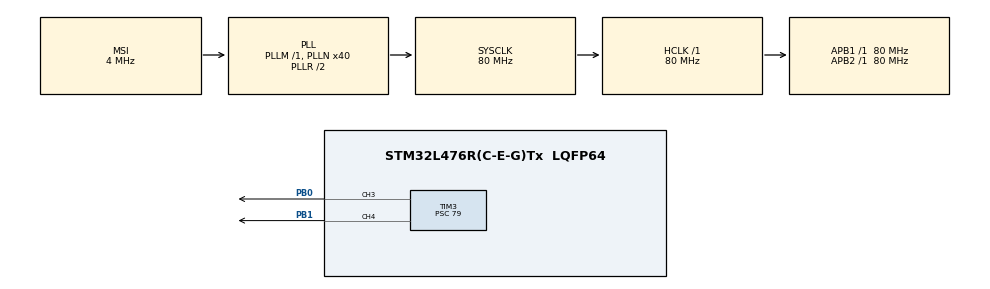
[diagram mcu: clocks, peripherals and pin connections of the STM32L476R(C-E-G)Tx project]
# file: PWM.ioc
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Mcu.Family=STM32L4
Mcu.Name=STM32L476R(C-E-G)Tx
Mcu.Package=LQFP64
NVIC.PriorityGroup=NVIC_PRIORITYGROUP_4
PA13\ (JTMS-SWDIO).Mode=Serial_Wire
PA13\ (JTMS-SWDIO).Signal=SYS_JTMS-SWDIO
PA14\ (JTCK-SWCLK).Mode=Serial_Wire
PA14\ (JTCK-SWCLK).Signal=SYS_JTCK-SWCLK
PB0.Signal=S_TIM3_CH3
PB1.Signal=S_TIM3_CH4
ProjectManager.HeapSize=0x200
ProjectManager.StackSize=0x400
ProjectManager.TargetToolchain=MDK-ARM V5.32
RCC.ADCFreq_Value=16000000
RCC.AHBFreq_Value=80000000
RCC.APB1Freq_Value=80000000
RCC.APB1TimFreq_Value=80000000
RCC.APB2Freq_Value=80000000
RCC.APB2TimFreq_Value=80000000
RCC.CortexFreq_Value=80000000
RCC.HCLKFreq_Value=80000000
RCC.HSE_VALUE=8000000
RCC.HSI_VALUE=16000000
RCC.LSE_VALUE=32768
RCC.MSI_VALUE=4000000
RCC.PLLN=40
RCC.SYSCLKFreq_VALUE=80000000
RCC.SYSCLKSource=RCC_SYSCLKSOURCE_PLLCLK
RCC.USBFreq_Value=16000000
RCC.VCOOutputFreq_Value=160000000
SH.S_TIM3_CH3.0=TIM3_CH3,PWM Generation3 CH3
SH.S_TIM3_CH4.0=TIM3_CH4,PWM Generation4 CH4
TIM3.Channel-PWM\ Generation3\ CH3=TIM_CHANNEL_3
TIM3.Channel-PWM\ Generation4\ CH4=TIM_CHANNEL_4
TIM3.Period=2000
TIM3.Prescaler=79
VP_TIM3_VS_ClockSourceINT.Mode=Internal
board=custom

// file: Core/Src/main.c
/* USER CODE BEGIN Header */
/**
  ******************************************************************************
  * @file           : main.c
  * @brief          : Main program body
  ******************************************************************************
  * @attention
  *
  * Copyright (c) 2026 STMicroelectronics.
  * All rights reserved.
  *
  * This software is licensed under terms that can be found in the LICENSE file
  * in the root directory of this software component.
  * If no LICENSE file comes with this software, it is provided AS-IS.
  *
  ******************************************************************************
  */
/* USER CODE END Header */
#include "main.h"

TIM_HandleTypeDef htim3;

/* USER CODE BEGIN PV */
void pwm_set_duty(TIM_HandleTypeDef *htim, uint32_t Channel, uint8_t duty)
{

	uint32_t ccr;
	if(duty>100)
	{
		duty=100;
	}
	ccr=((htim->Instance->ARR+1)*duty)/100;
	__HAL_TIM_SET_COMPARE(htim, Channel, ccr);
}
/* USER CODE END PV */

void SystemClock_Config(void);
static void MX_GPIO_Init(void);
static void MX_TIM3_Init(void);

int main(void)
{

  /* MCU Configuration--------------------------------------------------------*/

  /* Reset of all peripherals, Initializes the Flash interface and the Systick. */
  HAL_Init();

  /* Configure the system clock */
  SystemClock_Config();

  /* Initialize all configured peripherals */
  MX_GPIO_Init();
  MX_TIM3_Init();
  /* USER CODE BEGIN 2 */
	HAL_TIM_PWM_Start(&htim3, TIM_CHANNEL_3);
	HAL_TIM_PWM_Start(&htim3, TIM_CHANNEL_4);
	//thay doi duty cycle
	//htim3.Instance->CCR3 =1999;

  /* USER CODE END 2 */

  /* Infinite loop */
  while (1)
  {

    /* USER CODE BEGIN 3 */

		for(uint16_t i=0;i<=100;i++)
		{
			//pwm_set_duty(&htim3, TIM_CHANNEL_3, i);
			pwm_set_duty(&htim3, TIM_CHANNEL_4, i);
			HAL_Delay(5);
		}
  }
  /* USER CODE END 3 */
}

void SystemClock_Config(void)
{
  RCC_OscInitTypeDef RCC_OscInitStruct = {0};
  RCC_ClkInitTypeDef RCC_ClkInitStruct = {0};

  /** Configure the main internal regulator output voltage
  */
  if (HAL_PWREx_ControlVoltageScaling(PWR_REGULATOR_VOLTAGE_SCALE1) != HAL_OK)
  {
    Error_Handler();
  }

  /** Initializes the RCC Oscillators according to the specified parameters
  * in the RCC_OscInitTypeDef structure.
  */
  RCC_OscInitStruct.OscillatorType = RCC_OSCILLATORTYPE_MSI;
  RCC_OscInitStruct.MSIState = RCC_MSI_ON;
  RCC_OscInitStruct.MSICalibrationValue = 0;
  RCC_OscInitStruct.MSIClockRange = RCC_MSIRANGE_6;
  RCC_OscInitStruct.PLL.PLLState = RCC_PLL_ON;
  RCC_OscInitStruct.PLL.PLLSource = RCC_PLLSOURCE_MSI;
  RCC_OscInitStruct.PLL.PLLM = 1;
  RCC_OscInitStruct.PLL.PLLN = 40;
  RCC_OscInitStruct.PLL.PLLP = RCC_PLLP_DIV7;
  RCC_OscInitStruct.PLL.PLLQ = RCC_PLLQ_DIV2;
  RCC_OscInitStruct.PLL.PLLR = RCC_PLLR_DIV2;
  if (HAL_RCC_OscConfig(&RCC_OscInitStruct) != HAL_OK)
  {
    Error_Handler();
  }

  /** Initializes the CPU, AHB and APB buses clocks
  */
  RCC_ClkInitStruct.ClockType = RCC_CLOCKTYPE_HCLK|RCC_CLOCKTYPE_SYSCLK
                              |RCC_CLOCKTYPE_PCLK1|RCC_CLOCKTYPE_PCLK2;
  RCC_ClkInitStruct.SYSCLKSource = RCC_SYSCLKSOURCE_PLLCLK;
  RCC_ClkInitStruct.AHBCLKDivider = RCC_SYSCLK_DIV1;
  RCC_ClkInitStruct.APB1CLKDivider = RCC_HCLK_DIV1;
  RCC_ClkInitStruct.APB2CLKDivider = RCC_HCLK_DIV1;

  if (HAL_RCC_ClockConfig(&RCC_ClkInitStruct, FLASH_LATENCY_4) != HAL_OK)
  {
    Error_Handler();
  }
}

static void MX_TIM3_Init(void)
{

  TIM_ClockConfigTypeDef sClockSourceConfig = {0};
  TIM_MasterConfigTypeDef sMasterConfig = {0};
  TIM_OC_InitTypeDef sConfigOC = {0};

  htim3.Instance = TIM3;
  htim3.Init.Prescaler = 79;
  htim3.Init.CounterMode = TIM_COUNTERMODE_UP;
  htim3.Init.Period = 2000;
  htim3.Init.ClockDivision = TIM_CLOCKDIVISION_DIV1;
  htim3.Init.AutoReloadPreload = TIM_AUTORELOAD_PRELOAD_DISABLE;
  if (HAL_TIM_Base_Init(&htim3) != HAL_OK)
  {
    Error_Handler();
  }
  sClockSourceConfig.ClockSource = TIM_CLOCKSOURCE_INTERNAL;
  if (HAL_TIM_ConfigClockSource(&htim3, &sClockSourceConfig) != HAL_OK)
  {
    Error_Handler();
  }
  if (HAL_TIM_PWM_Init(&htim3) != HAL_OK)
  {
    Error_Handler();
  }
  sMasterConfig.MasterOutputTrigger = TIM_TRGO_RESET;
  sMasterConfig.MasterSlaveMode = TIM_MASTERSLAVEMODE_DISABLE;
  if (HAL_TIMEx_MasterConfigSynchronization(&htim3, &sMasterConfig) != HAL_OK)
  {
    Error_Handler();
  }
  sConfigOC.OCMode = TIM_OCMODE_PWM1;
  sConfigOC.Pulse = 0;
  sConfigOC.OCPolarity = TIM_OCPOLARITY_HIGH;
  sConfigOC.OCFastMode = TIM_OCFAST_DISABLE;
  if (HAL_TIM_PWM_ConfigChannel(&htim3, &sConfigOC, TIM_CHANNEL_3) != HAL_OK)
  {
    Error_Handler();
  }
  if (HAL_TIM_PWM_ConfigChannel(&htim3, &sConfigOC, TIM_CHANNEL_4) != HAL_OK)
  {
    Error_Handler();
  }
  HAL_TIM_MspPostInit(&htim3);

}

static void MX_GPIO_Init(void)
{

  /* GPIO Ports Clock Enable */
  __HAL_RCC_GPIOB_CLK_ENABLE();
  __HAL_RCC_GPIOA_CLK_ENABLE();

}

void Error_Handler(void)
{
  __disable_irq();
  while (1)
  {
  }
}
